# ATSAM4SD16B register map
Vendor: Atmel; File version: 0
CPU: CM4 r0p1, selectable endian, no MPU, no FPU, 0x4 interrupt priority bits, 0x0 interrupts
Registers are 32-bit, read-write, no defined reset value unless marked. A register's access mark holds for its fields unless they carry their own. Offsets are from the block's base; [hi:lo] are bit positions; {n}, {i} and the like mark numbered series.

## HSMCI — High Speed MultiMedia Card Interface
Base 0x40000000; register names take the prefix HSMCI_
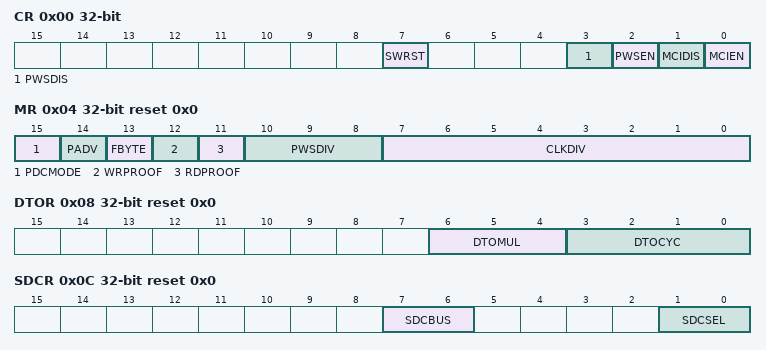
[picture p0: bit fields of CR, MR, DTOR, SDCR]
0x00 CR wo — Control Register
  [7] SWRST — Software Reset
  [3] PWSDIS — Power Save Mode Disable
  [2] PWSEN — Power Save Mode Enable
  [1] MCIDIS — Multi-Media Interface Disable
  [0] MCIEN — Multi-Media Interface Enable
0x04 MR reset 0x0 — Mode Register
  [15] PDCMODE — PDC-oriented Mode
  [14] PADV — Padding Value
  [13] FBYTE — Force Byte Transfer
  [12] WRPROOF — Write Proof Enable
  [11] RDPROOF — Read Proof Enable
  [10:8] PWSDIV — Power Saving Divider
  [7:0] CLKDIV — Clock Divider
0x08 DTOR reset 0x0 — Data Timeout Register
  [6:4] DTOMUL — Data Timeout Multiplier
    0=DTOCYC; 1=DTOCYC x 16; 2=DTOCYC x 128; 3=DTOCYC x 256; 4=DTOCYC x 1024; 5=DTOCYC x 4096; 6=DTOCYC x 65536; 7=DTOCYC x 1048576
  [3:0] DTOCYC — Data Timeout Cycle Number
0x0C SDCR reset 0x0 — SD/SDIO Card Register
  [7:6] SDCBUS — SDCard/SDIO Bus Width
    0=1 bit; 2=4 bits; 3=8 bits
  [1:0] SDCSEL — SDCard/SDIO Slot
    0=SLOTA (Slot A is selected.); 1=SLOTB; 2=SLOTC; 3=SLOTD
0x10 ARGR reset 0x0 — Argument Register
  [31:0] ARG — Command Argument
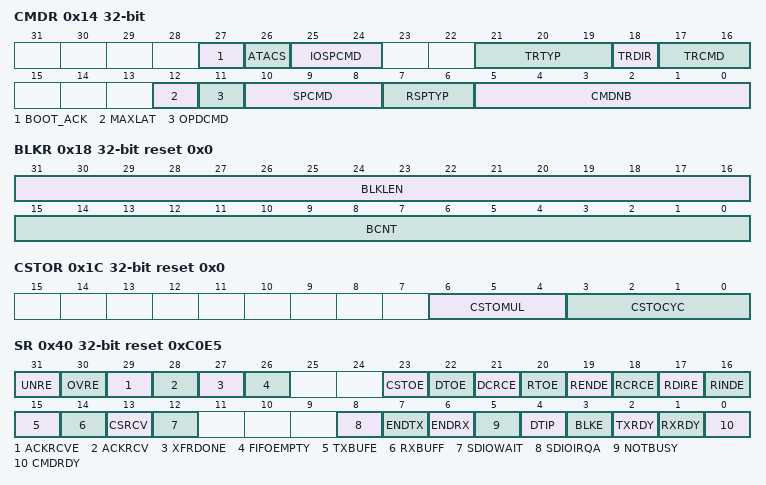
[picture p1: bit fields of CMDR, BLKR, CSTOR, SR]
0x14 CMDR wo — Command Register
  [27] BOOT_ACK — Boot Operation Acknowledge
  [26] ATACS — ATA with Command Completion Signal
    0=NORMAL (Normal operation mode.); 1=COMPLETION (This bit indicates that a completion signal is expected within a programmed amount of time (HSMCI_CSTOR).)
  [25:24] IOSPCMD — SDIO Special Command
    0=STD (Not an SDIO Special Command); 1=SUSPEND (SDIO Suspend Command); 2=RESUME (SDIO Resume Command)
  [21:19] TRTYP — Transfer Type
    0=SINGLE (MMC/SD Card Single Block); 1=MULTIPLE (MMC/SD Card Multiple Block); 2=STREAM (MMC Stream); 4=BYTE (SDIO Byte); 5=BLOCK (SDIO Block)
  [18] TRDIR — Transfer Direction
    0=WRITE; 1=READ
  [17:16] TRCMD — Transfer Command
    0=NO_DATA (No data transfer); 1=START_DATA (Start data transfer); 2=STOP_DATA (Stop data transfer)
  [12] MAXLAT — Max Latency for Command to Response
    0=5-cycle max latency; 1=64-cycle max latency
  [11] OPDCMD — Open Drain Command
    0=PUSHPULL (Push pull command.); 1=OPENDRAIN (Open drain command.)
  [10:8] SPCMD — Special Command
    0=STD (Not a special CMD.); 1=INIT (Initialization CMD: 74 clock cycles for initialization sequence.); 2=SYNC (Synchronized CMD: Wait for the end of the current data block transfer before sending the pending command.); 3=CE_ATA (CE-ATA Completion Signal disable Command. The host cancels the ability for the device to return a command completion signal on the command line.); 4=IT_CMD (Interrupt command: Corresponds to the Interrupt Mode (CMD40).); 5=IT_RESP (Interrupt response: Corresponds to the Interrupt Mode (CMD40).); 6=BOR (Boot Operation Request. Start a boot operation mode, the host processor can read boot data from the MMC device directly.); 7=EBO (End Boot Operation. This command allows the host processor to terminate the boot operation mode.)
  [7:6] RSPTYP — Response Type
    0=NORESP (No response); 1=48_BIT (48-bit response); 2=136_BIT (136-bit response); 3=R1B (R1b response type)
  [5:0] CMDNB — Command Number
0x18 BLKR reset 0x0 — Block Register
  [31:16] BLKLEN — Data Block Length
  [15:0] BCNT — MMC/SDIO Block Count - SDIO Byte Count
0x1C CSTOR reset 0x0 — Completion Signal Timeout Register
  [6:4] CSTOMUL — Completion Signal Timeout Multiplier
    0=CSTOCYC x 1; 1=CSTOCYC x 16; 2=CSTOCYC x 128; 3=CSTOCYC x 256; 4=CSTOCYC x 1024; 5=CSTOCYC x 4096; 6=CSTOCYC x 65536; 7=CSTOCYC x 1048576
  [3:0] CSTOCYC — Completion Signal Timeout Cycle Number
{0x20+4i} RSPR[{i}] ro (i=0..3) — Response Register
  [31:0] RSP — Response
0x30 RDR ro reset 0x0 — Receive Data Register
  [31:0] DATA — Data to Read
0x34 TDR wo — Transmit Data Register
  [31:0] DATA — Data to Write
0x40 SR ro reset 0xC0E5 — Status Register
  [31] UNRE — Underrun (if FERRCTRL = 1, cleared by writing in HSMCI_CMDR or cleared on read if FERRCTRL = 0)
  [30] OVRE — Overrun (if FERRCTRL = 1, cleared by writing in HSMCI_CMDR or cleared on read if FERRCTRL = 0)
  [29] ACKRCVE — Boot Operation Acknowledge Error (cleared on read)
  [28] ACKRCV — Boot Operation Acknowledge Received (cleared on read)
  [27] XFRDONE — Transfer Done flag
  [26] FIFOEMPTY — FIFO empty flag
  [23] CSTOE — Completion Signal Time-out Error (cleared on read)
  [22] DTOE — Data Time-out Error (cleared on read)
  [21] DCRCE — Data CRC Error (cleared on read)
  [20] RTOE — Response Time-out Error (cleared by writing in HSMCI_CMDR)
  [19] RENDE — Response End Bit Error (cleared by writing in HSMCI_CMDR)
  [18] RCRCE — Response CRC Error (cleared by writing in HSMCI_CMDR)
  [17] RDIRE — Response Direction Error (cleared by writing in HSMCI_CMDR)
  [16] RINDE — Response Index Error (cleared by writing in HSMCI_CMDR)
  [15] TXBUFE — TX Buffer Empty (cleared by writing HSMCI_TCR or HSMCI_TNCR(1))
  [14] RXBUFF — RX Buffer Full (cleared by writing HSMCI_RCR or HSMCI_RNCR(1))
  [13] CSRCV — CE-ATA Completion Signal Received (cleared on read)
  [12] SDIOWAIT — SDIO Read Wait Operation Status
  [8] SDIOIRQA — SDIO Interrupt for Slot A (cleared on read)
  [7] ENDTX — End of TX Buffer (cleared by writing HSMCI_TCR or HSMCI_TNCR(1))
  [6] ENDRX — End of RX Buffer (cleared by writing HSMCI_RCR or HSMCI_RNCR(1))
  [5] NOTBUSY — HSMCI Not Busy
  [4] DTIP — Data Transfer in Progress (cleared at the end of CRC16 calculation)
  [3] BLKE — Data Block Ended (cleared on read)
  [2] TXRDY — Transmit Ready (cleared by writing in HSMCI_TDR)
  [1] RXRDY — Receiver Ready (cleared by reading HSMCI_RDR)
  [0] CMDRDY — Command Ready (cleared by writing in HSMCI_CMDR)
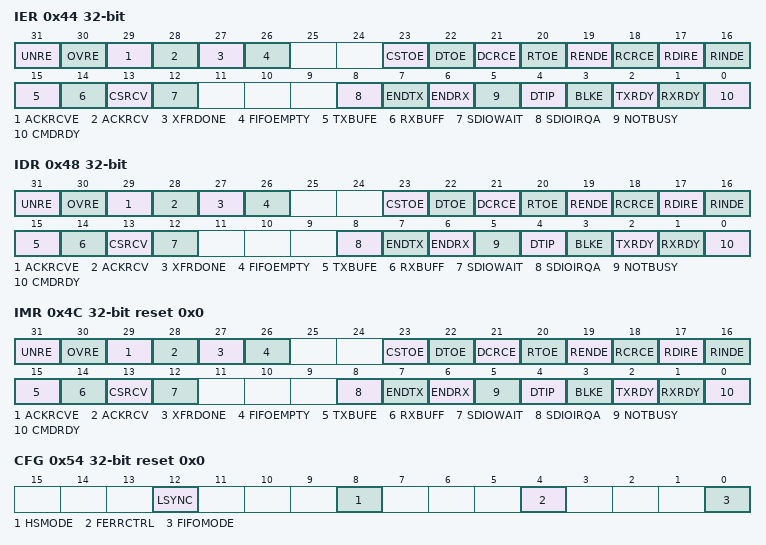
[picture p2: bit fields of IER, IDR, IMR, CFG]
0x44 IER wo — Interrupt Enable Register
  [31] UNRE — Underrun Interrupt Enable
  [30] OVRE — Overrun Interrupt Enable
  [29] ACKRCVE — Boot Acknowledge Error Interrupt Enable
  [28] ACKRCV — Boot Acknowledge Interrupt Enable
  [27] XFRDONE — Transfer Done Interrupt enable
  [26] FIFOEMPTY — FIFO empty Interrupt enable
  [23] CSTOE — Completion Signal Timeout Error Interrupt Enable
  [22] DTOE — Data Time-out Error Interrupt Enable
  [21] DCRCE — Data CRC Error Interrupt Enable
  [20] RTOE — Response Time-out Error Interrupt Enable
  [19] RENDE — Response End Bit Error Interrupt Enable
  [18] RCRCE — Response CRC Error Interrupt Enable
  [17] RDIRE — Response Direction Error Interrupt Enable
  [16] RINDE — Response Index Error Interrupt Enable
  [15] TXBUFE — Transmit Buffer Empty Interrupt Enable
  [14] RXBUFF — Receive Buffer Full Interrupt Enable
  [13] CSRCV — Completion Signal Received Interrupt Enable
  [12] SDIOWAIT — SDIO Read Wait Operation Status Interrupt Enable
  [8] SDIOIRQA — SDIO Interrupt for Slot A Interrupt Enable
  [7] ENDTX — End of Transmit Buffer Interrupt Enable
  [6] ENDRX — End of Receive Buffer Interrupt Enable
  [5] NOTBUSY — Data Not Busy Interrupt Enable
  [4] DTIP — Data Transfer in Progress Interrupt Enable
  [3] BLKE — Data Block Ended Interrupt Enable
  [2] TXRDY — Transmit Ready Interrupt Enable
  [1] RXRDY — Receiver Ready Interrupt Enable
  [0] CMDRDY — Command Ready Interrupt Enable
0x48 IDR wo — Interrupt Disable Register
  [31] UNRE — Underrun Interrupt Disable
  [30] OVRE — Overrun Interrupt Disable
  [29] ACKRCVE — Boot Acknowledge Error Interrupt Disable
  [28] ACKRCV — Boot Acknowledge Interrupt Disable
  [27] XFRDONE — Transfer Done Interrupt Disable
  [26] FIFOEMPTY — FIFO empty Interrupt Disable
  [23] CSTOE — Completion Signal Time out Error Interrupt Disable
  [22] DTOE — Data Time-out Error Interrupt Disable
  [21] DCRCE — Data CRC Error Interrupt Disable
  [20] RTOE — Response Time-out Error Interrupt Disable
  [19] RENDE — Response End Bit Error Interrupt Disable
  [18] RCRCE — Response CRC Error Interrupt Disable
  [17] RDIRE — Response Direction Error Interrupt Disable
  [16] RINDE — Response Index Error Interrupt Disable
  [15] TXBUFE — Transmit Buffer Empty Interrupt Disable
  [14] RXBUFF — Receive Buffer Full Interrupt Disable
  [13] CSRCV — Completion Signal received interrupt Disable
  [12] SDIOWAIT — SDIO Read Wait Operation Status Interrupt Disable
  [8] SDIOIRQA — SDIO Interrupt for Slot A Interrupt Disable
  [7] ENDTX — End of Transmit Buffer Interrupt Disable
  [6] ENDRX — End of Receive Buffer Interrupt Disable
  [5] NOTBUSY — Data Not Busy Interrupt Disable
  [4] DTIP — Data Transfer in Progress Interrupt Disable
  [3] BLKE — Data Block Ended Interrupt Disable
  [2] TXRDY — Transmit Ready Interrupt Disable
  [1] RXRDY — Receiver Ready Interrupt Disable
  [0] CMDRDY — Command Ready Interrupt Disable
0x4C IMR ro reset 0x0 — Interrupt Mask Register
  [31] UNRE — Underrun Interrupt Mask
  [30] OVRE — Overrun Interrupt Mask
  [29] ACKRCVE — Boot Operation Acknowledge Error Interrupt Mask
  [28] ACKRCV — Boot Operation Acknowledge Received Interrupt Mask
  [27] XFRDONE — Transfer Done Interrupt Mask
  [26] FIFOEMPTY — FIFO Empty Interrupt Mask
  [23] CSTOE — Completion Signal Time-out Error Interrupt Mask
  [22] DTOE — Data Time-out Error Interrupt Mask
  [21] DCRCE — Data CRC Error Interrupt Mask
  [20] RTOE — Response Time-out Error Interrupt Mask
  [19] RENDE — Response End Bit Error Interrupt Mask
  [18] RCRCE — Response CRC Error Interrupt Mask
  [17] RDIRE — Response Direction Error Interrupt Mask
  [16] RINDE — Response Index Error Interrupt Mask
  [15] TXBUFE — Transmit Buffer Empty Interrupt Mask
  [14] RXBUFF — Receive Buffer Full Interrupt Mask
  [13] CSRCV — Completion Signal Received Interrupt Mask
  [12] SDIOWAIT — SDIO Read Wait Operation Status Interrupt Mask
  [8] SDIOIRQA — SDIO Interrupt for Slot A Interrupt Mask
  [7] ENDTX — End of Transmit Buffer Interrupt Mask
  [6] ENDRX — End of Receive Buffer Interrupt Mask
  [5] NOTBUSY — Data Not Busy Interrupt Mask
  [4] DTIP — Data Transfer in Progress Interrupt Mask
  [3] BLKE — Data Block Ended Interrupt Mask
  [2] TXRDY — Transmit Ready Interrupt Mask
  [1] RXRDY — Receiver Ready Interrupt Mask
  [0] CMDRDY — Command Ready Interrupt Mask
0x54 CFG reset 0x0 — Configuration Register
  [12] LSYNC — Synchronize on the last block
  [8] HSMODE — High Speed Mode
  [4] FERRCTRL — Flow Error flag reset control mode
  [0] FIFOMODE — HSMCI Internal FIFO control mode
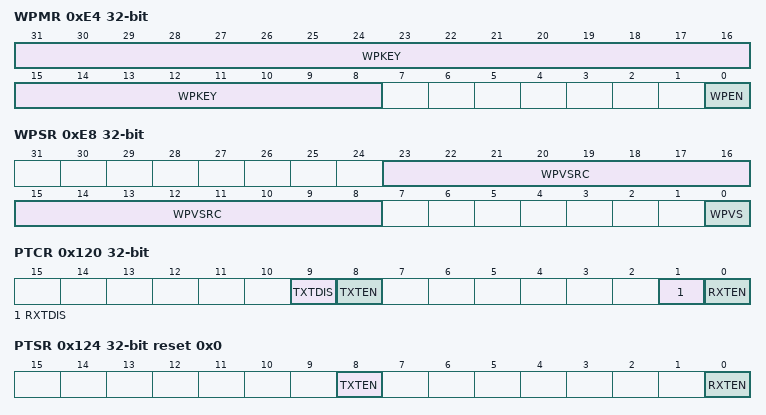
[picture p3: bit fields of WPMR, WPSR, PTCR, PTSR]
0xE4 WPMR — Write Protection Mode Register
  [31:8] WPKEY — Write Protect Key
    0x4D4349=PASSWD (Writing any other value in this field aborts the write operation of the WPEN bit.Always reads as 0.)
  [0] WPEN — Write Protect Enable
0xE8 WPSR ro — Write Protection Status Register
  [23:8] WPVSRC — Write Protection Violation Source
  [0] WPVS — Write Protection Violation Status
0x100 RPR reset 0x0 — Receive Pointer Register
  [31:0] RXPTR
0x104 RCR reset 0x0 — Receive Counter Register
  [15:0] RXCTR
0x108 TPR reset 0x0 — Transmit Pointer Register
  [31:0] TXPTR — Transmit Counter Register
0x10C TCR reset 0x0 — Transmit Counter Register
  [15:0] TXCTR
0x110 RNPR reset 0x0 — Receive Next Pointer Register
  [31:0] RXNPTR — Receive Next Pointer
0x114 RNCR reset 0x0 — Receive Next Counter Register
  [15:0] RXNCTR — Receive Next Counter
0x118 TNPR reset 0x0 — Transmit Next Pointer Register
  [31:0] TXNPTR — Transmit Next Pointer
0x11C TNCR reset 0x0 — Transmit Next Counter Register
  [15:0] TXNCTR — Transmit Counter Next
0x120 PTCR wo — Transfer Control Register
  [9] TXTDIS — Transmitter Transfer Disable
  [8] TXTEN — Transmitter Transfer Enable
  [1] RXTDIS — Receiver Transfer Disable
  [0] RXTEN — Receiver Transfer Enable
0x124 PTSR ro reset 0x0 — Transfer Status Register
  [8] TXTEN — Transmitter Transfer Enable
  [0] RXTEN — Receiver Transfer Enable
{0x200+4i} FIFO[{i}] (i=0..255) — FIFO Memory Aperture0
  [31:0] DATA — Data to Read or Data to Write
